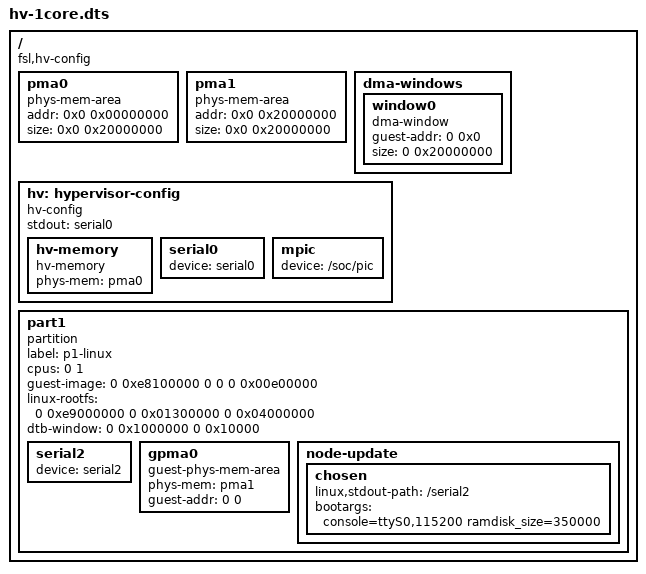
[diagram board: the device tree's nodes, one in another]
/dts-v1/;

/ {
	compatible = "fsl,hv-config";

	// =====================================================
	// Physical Memory Areas
	// =====================================================
	pma0:pma0 {
		compatible = "phys-mem-area";
		addr = <0x0 0x00000000>;
		size = <0x0 0x20000000>;  // 512MB
	};
	pma1:pma1 {
		compatible = "phys-mem-area";
		addr = <0x0 0x20000000>;
		size = <0x0 0x20000000>;  // 512MB
	};

	dma-windows {
		window0: window0 {
			compatible = "dma-window";
			guest-addr = <0 0x0>;
			size = <0 0x20000000>;
		};
	};

	// =====================================================
	// Hypervisor Config
	// =====================================================
	hv:hypervisor-config {
		compatible = "hv-config";
		stdout = <&serial0>;

		hv-memory {
			compatible = "hv-memory";
			phys-mem = <&pma0>;
		};

		serial0:serial0 {
			device = "serial0";
		};

		mpic {
			device = "/soc/pic";
		};
	};

	// =====================================================
	// Partition 1
	// =====================================================
	part1 {
		compatible = "partition";
		label = "p1-linux";
		cpus = <0 1>;
		guest-image = <0 0xe8100000 0 0 0 0x00e00000>;
		linux-rootfs = <0 0xe9000000 0 0x01300000 0 0x04000000>;
		dtb-window = <0 0x1000000 0 0x10000>;

		serial2 {
			device = "serial2";
		};

		gpma0 {
			compatible = "guest-phys-mem-area";
			phys-mem = <&pma1>;
			guest-addr = <0 0>;
		};

		node-update {
			chosen {
				/* We should probably provide fixup for linux,stdout-path
				 * similar to aliases.
				 */
				linux,stdout-path = "/serial2";
				bootargs = "console=ttyS0,115200 ramdisk_size=350000";
			};
		};
	};
};
